# STM32F30xxx register map
File version: 1.0
Registers are 32-bit, read-write, reset 0x0 unless marked. A register's access mark holds for its fields unless they carry their own. Offsets are from the block's base; [hi:lo] are bit positions; {n}, {i} and the like mark numbered series.

## PWR — Power control
Base 0x40007000
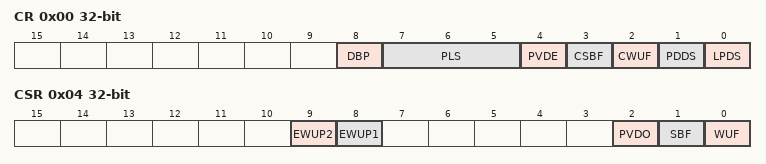
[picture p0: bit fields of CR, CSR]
0x00 CR — power control register
  [8] DBP — Disable backup domain write protection
  [7:5] PLS — PVD level selection
  [4] PVDE — Power voltage detector enable
  [3] CSBF — Clear standby flag
  [2] CWUF — Clear wakeup flag
  [1] PDDS — Power down deepsleep
  [0] LPDS — Low-power deep sleep
0x04 CSR access per field — power control/status register
  [9] EWUP2 rw — Enable WKUP2 pin
  [8] EWUP1 rw — Enable WKUP1 pin
  [2] PVDO ro — PVD output
  [1] SBF ro — Standby flag
  [0] WUF ro — Wakeup flag

## USB_FS — Universal serial bus full-speed device interface
Base 0x40005C00
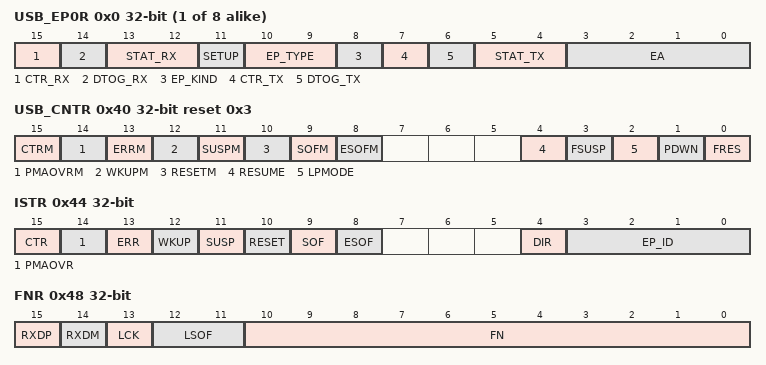
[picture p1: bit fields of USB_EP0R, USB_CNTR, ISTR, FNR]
{0x0+4i} USB_EP{i}R access per field (i=0..7) — endpoint {i} register
  [15] CTR_RX rw — Correct transfer for reception
  [14] DTOG_RX rw — Data Toggle, for reception transfers
  [13:12] STAT_RX rw — Status bits, for reception transfers
  [11] SETUP ro — Setup transaction completed
  [10:9] EP_TYPE rw — Endpoint type
  [8] EP_KIND rw — Endpoint kind
  [7] CTR_TX rw — Correct Transfer for transmission
  [6] DTOG_TX rw — Data Toggle, for transmission transfers
  [5:4] STAT_TX rw — Status bits, for transmission transfers
  [3:0] EA rw — Endpoint address
0x40 USB_CNTR reset 0x3 — control register
  [15] CTRM — Correct transfer interrupt mask
  [14] PMAOVRM — Packet memory area over / underrun interrupt mask
  [13] ERRM — Error interrupt mask
  [12] WKUPM — Wakeup interrupt mask
  [11] SUSPM — Suspend mode interrupt mask
  [10] RESETM — USB reset interrupt mask
  [9] SOFM — Start of frame interrupt mask
  [8] ESOFM — Expected start of frame interrupt mask
  [4] RESUME — Resume request
  [3] FSUSP — Force suspend
  [2] LPMODE — Low-power mode
  [1] PDWN — Power down
  [0] FRES — Force USB Reset
0x44 ISTR access per field — interrupt status register
  [15] CTR ro — Correct transfer
  [14] PMAOVR rw — Packet memory area over / underrun
  [13] ERR rw — Error
  [12] WKUP rw — Wakeup
  [11] SUSP rw — Suspend mode request
  [10] RESET rw — reset request
  [9] SOF rw — start of frame
  [8] ESOF rw — Expected start frame
  [4] DIR ro — Direction of transaction
  [3:0] EP_ID ro — Endpoint Identifier
0x48 FNR ro — frame number register
  [15] RXDP — Receive data + line status
  [14] RXDM — Receive data - line status
  [13] LCK — Locked
  [12:11] LSOF — Lost SOF
  [10:0] FN — Frame number
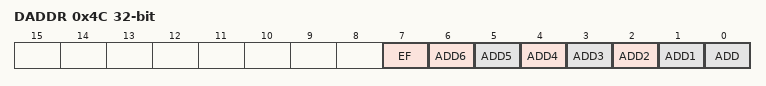
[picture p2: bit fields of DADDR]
0x4C DADDR — device address
  [7] EF — Enable function
  [n] ADD{n} (n=1..6) — Device address
  [0] ADD — Device address
0x50 BTABLE — Buffer table address
  [15:3] BTABLE — Buffer table

## IWDG — Independent watchdog
Base 0x40003000
0x00 KR wo — Key register
  [15:0] KEY — Key value
0x04 PR — Prescaler register
  [2:0] PR — Prescaler divider
0x08 RLR reset 0xFFF — Reload register
  [11:0] RL — Watchdog counter reload value
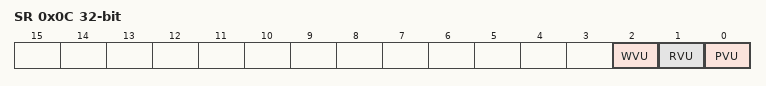
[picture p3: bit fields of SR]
0x0C SR ro — Status register
  [2] WVU — Watchdog counter window value update
  [1] RVU — Watchdog counter reload value update
  [0] PVU — Watchdog prescaler value update
0x10 WINR reset 0xFFF — Window register
  [11:0] WIN — Watchdog counter window value

## WWDG — Window watchdog
Base 0x40002C00
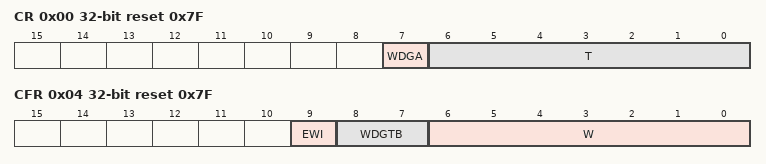
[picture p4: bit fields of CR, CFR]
0x00 CR reset 0x7F — Control register
  [7] WDGA — Activation bit
  [6:0] T — 7-bit counter
0x04 CFR reset 0x7F — Configuration register
  [9] EWI — Early wakeup interrupt
  [8:7] WDGTB — Timer base
  [6:0] W — 7-bit window value
0x08 SR — Status register
  [0] EWIF — Early wakeup interrupt flag

## TIM6 — Basic timers
Base 0x40001000
Same registers: TIM7 0x40001400
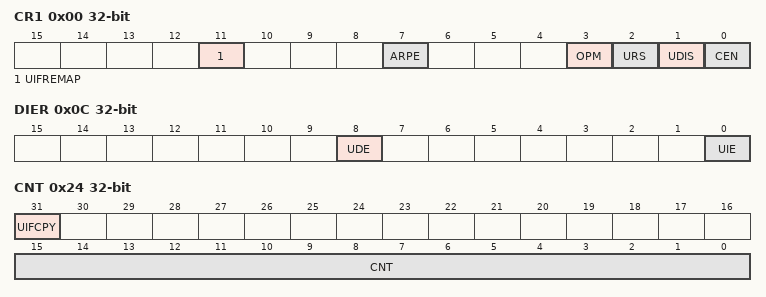
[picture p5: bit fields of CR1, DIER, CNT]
0x00 CR1 — control register 1
  [11] UIFREMAP — UIF status bit remapping
  [7] ARPE — Auto-reload preload enable
  [3] OPM — One-pulse mode
  [2] URS — Update request source
  [1] UDIS — Update disable
  [0] CEN — Counter enable
0x04 CR2 — control register 2
  [6:4] MMS — Master mode selection
0x0C DIER — DMA/Interrupt enable register
  [8] UDE — Update DMA request enable
  [0] UIE — Update interrupt enable
0x10 SR — status register
  [0] UIF — Update interrupt flag
0x14 EGR wo — event generation register
  [0] UG — Update generation
0x24 CNT access per field — counter
  [31] UIFCPY ro — UIF Copy
  [15:0] CNT rw — Low counter value
0x28 PSC — prescaler
  [15:0] PSC — Prescaler value
0x2C ARR — auto-reload register
  [15:0] ARR — Low Auto-reload value
